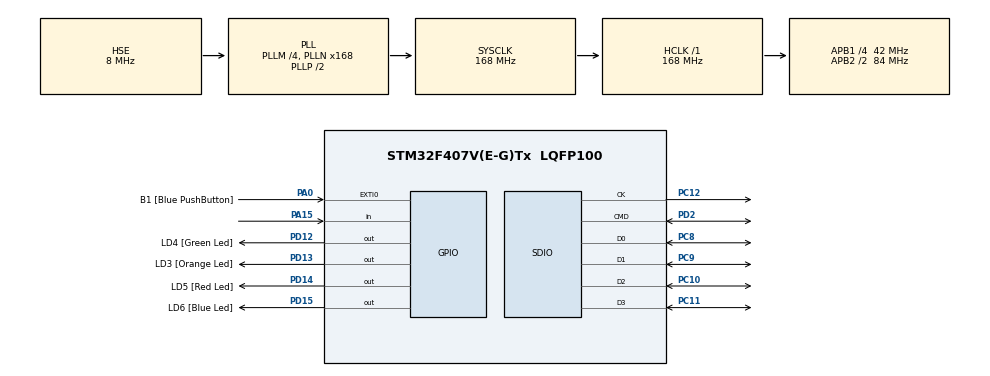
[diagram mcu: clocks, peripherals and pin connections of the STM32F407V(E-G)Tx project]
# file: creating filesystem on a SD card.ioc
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Dma.Request0=SDIO_RX
Dma.Request1=SDIO_TX
Dma.SDIO_RX.0.Direction=DMA_PERIPH_TO_MEMORY
Dma.SDIO_RX.0.FIFOMode=DMA_FIFOMODE_ENABLE
Dma.SDIO_RX.0.FIFOThreshold=DMA_FIFO_THRESHOLD_FULL
Dma.SDIO_RX.0.Instance=DMA2_Stream3
Dma.SDIO_RX.0.MemBurst=DMA_MBURST_INC4
Dma.SDIO_RX.0.MemDataAlignment=DMA_MDATAALIGN_WORD
Dma.SDIO_RX.0.MemInc=DMA_MINC_ENABLE
Dma.SDIO_RX.0.Mode=DMA_PFCTRL
Dma.SDIO_RX.0.PeriphBurst=DMA_PBURST_INC4
Dma.SDIO_RX.0.PeriphDataAlignment=DMA_PDATAALIGN_WORD
Dma.SDIO_RX.0.PeriphInc=DMA_PINC_DISABLE
Dma.SDIO_RX.0.Priority=DMA_PRIORITY_LOW
Dma.SDIO_TX.1.Direction=DMA_MEMORY_TO_PERIPH
Dma.SDIO_TX.1.FIFOMode=DMA_FIFOMODE_ENABLE
Dma.SDIO_TX.1.FIFOThreshold=DMA_FIFO_THRESHOLD_FULL
Dma.SDIO_TX.1.Instance=DMA2_Stream6
Dma.SDIO_TX.1.MemBurst=DMA_MBURST_INC4
Dma.SDIO_TX.1.MemDataAlignment=DMA_MDATAALIGN_WORD
Dma.SDIO_TX.1.MemInc=DMA_MINC_ENABLE
Dma.SDIO_TX.1.Mode=DMA_PFCTRL
Dma.SDIO_TX.1.PeriphBurst=DMA_PBURST_INC4
Dma.SDIO_TX.1.PeriphDataAlignment=DMA_PDATAALIGN_WORD
Dma.SDIO_TX.1.PeriphInc=DMA_PINC_DISABLE
Dma.SDIO_TX.1.Priority=DMA_PRIORITY_LOW
FATFS.BSP.number=1
FATFS.USE_DMA_CODE_SD=1
FATFS._MAX_SS=4096
FATFS._USE_LFN=1
FATFS0.BSP.STBoard=false
FATFS0.BSP.api=Unknown
FATFS0.BSP.i2caddr=0
FATFS0.BSP.instance=PA15
FATFS0.BSP.ip=GPIO
FATFS0.BSP.mode=Input
FATFS0.BSP.name=Detect_SDIO
FATFS0.BSP.solution=PA15
Mcu.Family=STM32F4
Mcu.Name=STM32F407V(E-G)Tx
Mcu.Package=LQFP100
NVIC.DMA2_Stream3_IRQn=true\:0\:0\:false\:false\:true\:false\:true
NVIC.DMA2_Stream6_IRQn=true\:0\:0\:false\:false\:true\:false\:true
NVIC.PriorityGroup=NVIC_PRIORITYGROUP_0
NVIC.SDIO_IRQn=true\:0\:0\:false\:false\:true\:true\:true
PA0-WKUP.GPIO_Label=B1 [Blue PushButton]
PA0-WKUP.Signal=GPXTI0
PA13.GPIO_Label=SWDIO
PA13.Mode=Serial_Wire
PA13.Signal=SYS_JTMS-SWDIO
PA14.GPIO_Label=SWCLK
PA14.Mode=Serial_Wire
PA14.Signal=SYS_JTCK-SWCLK
PA15.Signal=GPIO_Input
PC10.Mode=SD_4_bits_Wide_bus
PC10.Signal=SDIO_D2
PC11.Mode=SD_4_bits_Wide_bus
PC11.Signal=SDIO_D3
PC12.Mode=SD_4_bits_Wide_bus
PC12.Signal=SDIO_CK
PC8.Mode=SD_4_bits_Wide_bus
PC8.Signal=SDIO_D0
PC9.Mode=SD_4_bits_Wide_bus
PC9.Signal=SDIO_D1
PD12.GPIO_Label=LD4 [Green Led]
PD12.GPIO_PuPd=GPIO_NOPULL
PD12.GPIO_Speed=GPIO_SPEED_FREQ_LOW
PD12.Signal=GPIO_Output
PD13.GPIO_Label=LD3 [Orange Led]
PD13.GPIO_PuPd=GPIO_NOPULL
PD13.GPIO_Speed=GPIO_SPEED_FREQ_LOW
PD13.Signal=GPIO_Output
PD14.GPIO_Label=LD5 [Red Led]
PD14.GPIO_PuPd=GPIO_NOPULL
PD14.GPIO_Speed=GPIO_SPEED_FREQ_LOW
PD14.Signal=GPIO_Output
PD15.GPIO_Label=LD6 [Blue Led]
PD15.GPIO_PuPd=GPIO_NOPULL
PD15.GPIO_Speed=GPIO_SPEED_FREQ_LOW
PD15.Signal=GPIO_Output
PD2.Mode=SD_4_bits_Wide_bus
PD2.Signal=SDIO_CMD
PH0-OSC_IN.Mode=HSE-External-Oscillator
PH0-OSC_IN.Signal=RCC_OSC_IN
PH1-OSC_OUT.Mode=HSE-External-Oscillator
PH1-OSC_OUT.Signal=RCC_OSC_OUT
ProjectManager.HeapSize=0x400
ProjectManager.StackSize=0x800
ProjectManager.TargetToolchain=STM32CubeIDE
RCC.48MHZClocksFreq_Value=48000000
RCC.AHBFreq_Value=168000000
RCC.APB1CLKDivider=RCC_HCLK_DIV4
RCC.APB1Freq_Value=42000000
RCC.APB1TimFreq_Value=84000000
RCC.APB2CLKDivider=RCC_HCLK_DIV2
RCC.APB2Freq_Value=84000000
RCC.APB2TimFreq_Value=168000000
RCC.CortexFreq_Value=168000000
RCC.HCLKFreq_Value=168000000
RCC.HSE_VALUE=8000000
RCC.HSI_VALUE=16000000
RCC.LSE_VALUE=32768
RCC.PLLM=4
RCC.PLLN=168
RCC.PLLQ=7
RCC.PLLSourceVirtual=RCC_PLLSOURCE_HSE
RCC.SYSCLKFreq_VALUE=168000000
RCC.SYSCLKSource=RCC_SYSCLKSOURCE_PLLCLK
RCC.VCOOutputFreq_Value=336000000
SDIO.ClockDiv=5
VP_FATFS_VS_SDIO.Mode=SDIO
board=STM32F407G-DISC1

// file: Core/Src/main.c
/* USER CODE BEGIN Header */
/**
  ******************************************************************************
  * @file           : main.c
  * @brief          : Main program body
  ******************************************************************************
  * @attention
  *
  * <h2><center>&copy; Copyright (c) 2021 STMicroelectronics.
  * All rights reserved.</center></h2>
  *
  * This software component is licensed by ST under Ultimate Liberty license
  * SLA0044, the "License"; You may not use this file except in compliance with
  * the License. You may obtain a copy of the License at:
  *                             www.st.com/SLA0044
  *
  ******************************************************************************
  */
/* USER CODE END Header */
#include "main.h"
#include "fatfs.h"

SD_HandleTypeDef hsd;
DMA_HandleTypeDef hdma_sdio_rx;
DMA_HandleTypeDef hdma_sdio_tx;

void SystemClock_Config(void);
static void MX_GPIO_Init(void);
static void MX_DMA_Init(void);
static void MX_SDIO_SD_Init(void);

int main(void)
{
  /* USER CODE BEGIN 1 */
FRESULT res;
uint32_t byteswritten, bytesread;
uint8_t wtext[] = "stm32 fatfs works great!";
uint8_t rtext[_MAX_SS];
  /* USER CODE END 1 */

  /* MCU Configuration--------------------------------------------------------*/

  /* Reset of all peripherals, Initializes the Flash interface and the Systick. */
  HAL_Init();

  /* Configure the system clock */
  SystemClock_Config();

  /* Initialize all configured peripherals */
  MX_GPIO_Init();
  MX_DMA_Init();
  MX_SDIO_SD_Init();
  MX_FATFS_Init();
  /* USER CODE BEGIN 2 */
res=f_mount(&SDFatFS, (TCHAR const*)SDPath, 0);
res=f_mkfs((TCHAR const *)SDPath, FM_ANY, 0, rtext, sizeof(rtext));
res=f_open(&SDFile, "STM32.txt",FA_CREATE_ALWAYS | FA_WRITE);
res = f_write(&SDFile, wtext, strlen((char *)wtext), (void *)&byteswritten);
res=f_close(&SDFile);
res=f_mount(&SDFatFS, (TCHAR const*)NULL, 0);
  /* USER CODE END 2 */

  /* Infinite loop */
  while (1)
  {

  }
}

void SystemClock_Config(void)
{
  RCC_OscInitTypeDef RCC_OscInitStruct = {0};
  RCC_ClkInitTypeDef RCC_ClkInitStruct = {0};

  /** Configure the main internal regulator output voltage
  */
  __HAL_RCC_PWR_CLK_ENABLE();
  __HAL_PWR_VOLTAGESCALING_CONFIG(PWR_REGULATOR_VOLTAGE_SCALE1);
  /** Initializes the RCC Oscillators according to the specified parameters
  * in the RCC_OscInitTypeDef structure.
  */
  RCC_OscInitStruct.OscillatorType = RCC_OSCILLATORTYPE_HSE;
  RCC_OscInitStruct.HSEState = RCC_HSE_ON;
  RCC_OscInitStruct.PLL.PLLState = RCC_PLL_ON;
  RCC_OscInitStruct.PLL.PLLSource = RCC_PLLSOURCE_HSE;
  RCC_OscInitStruct.PLL.PLLM = 4;
  RCC_OscInitStruct.PLL.PLLN = 168;
  RCC_OscInitStruct.PLL.PLLP = RCC_PLLP_DIV2;
  RCC_OscInitStruct.PLL.PLLQ = 7;
  if (HAL_RCC_OscConfig(&RCC_OscInitStruct) != HAL_OK)
  {
    Error_Handler();
  }
  /** Initializes the CPU, AHB and APB buses clocks
  */
  RCC_ClkInitStruct.ClockType = RCC_CLOCKTYPE_HCLK|RCC_CLOCKTYPE_SYSCLK
                              |RCC_CLOCKTYPE_PCLK1|RCC_CLOCKTYPE_PCLK2;
  RCC_ClkInitStruct.SYSCLKSource = RCC_SYSCLKSOURCE_PLLCLK;
  RCC_ClkInitStruct.AHBCLKDivider = RCC_SYSCLK_DIV1;
  RCC_ClkInitStruct.APB1CLKDivider = RCC_HCLK_DIV4;
  RCC_ClkInitStruct.APB2CLKDivider = RCC_HCLK_DIV2;

  if (HAL_RCC_ClockConfig(&RCC_ClkInitStruct, FLASH_LATENCY_5) != HAL_OK)
  {
    Error_Handler();
  }
}

static void MX_SDIO_SD_Init(void)
{

  hsd.Instance = SDIO;
  hsd.Init.ClockEdge = SDIO_CLOCK_EDGE_RISING;
  hsd.Init.ClockBypass = SDIO_CLOCK_BYPASS_DISABLE;
  hsd.Init.ClockPowerSave = SDIO_CLOCK_POWER_SAVE_DISABLE;
  hsd.Init.BusWide = SDIO_BUS_WIDE_1B;
  hsd.Init.HardwareFlowControl = SDIO_HARDWARE_FLOW_CONTROL_DISABLE;
  hsd.Init.ClockDiv = 5;

}

static void MX_DMA_Init(void)
{

  /* DMA controller clock enable */
  __HAL_RCC_DMA2_CLK_ENABLE();

  /* DMA interrupt init */
  /* DMA2_Stream3_IRQn interrupt configuration */
  HAL_NVIC_SetPriority(DMA2_Stream3_IRQn, 0, 0);
  HAL_NVIC_EnableIRQ(DMA2_Stream3_IRQn);
  /* DMA2_Stream6_IRQn interrupt configuration */
  HAL_NVIC_SetPriority(DMA2_Stream6_IRQn, 0, 0);
  HAL_NVIC_EnableIRQ(DMA2_Stream6_IRQn);

}

static void MX_GPIO_Init(void)
{
  GPIO_InitTypeDef GPIO_InitStruct = {0};

  /* GPIO Ports Clock Enable */
  __HAL_RCC_GPIOH_CLK_ENABLE();
  __HAL_RCC_GPIOA_CLK_ENABLE();
  __HAL_RCC_GPIOD_CLK_ENABLE();
  __HAL_RCC_GPIOC_CLK_ENABLE();

  /*Configure GPIO pin Output Level */
  HAL_GPIO_WritePin(GPIOD, LD4_Pin|LD3_Pin|LD5_Pin|LD6_Pin, GPIO_PIN_RESET);

  /*Configure GPIO pin : B1_Pin */
  GPIO_InitStruct.Pin = B1_Pin;
  GPIO_InitStruct.Mode = GPIO_MODE_IT_RISING;
  GPIO_InitStruct.Pull = GPIO_NOPULL;
  HAL_GPIO_Init(B1_GPIO_Port, &GPIO_InitStruct);

  /*Configure GPIO pins : LD4_Pin LD3_Pin LD5_Pin LD6_Pin */
  GPIO_InitStruct.Pin = LD4_Pin|LD3_Pin|LD5_Pin|LD6_Pin;
  GPIO_InitStruct.Mode = GPIO_MODE_OUTPUT_PP;
  GPIO_InitStruct.Pull = GPIO_NOPULL;
  GPIO_InitStruct.Speed = GPIO_SPEED_FREQ_LOW;
  HAL_GPIO_Init(GPIOD, &GPIO_InitStruct);

  /*Configure GPIO pin : PA15 */
  GPIO_InitStruct.Pin = GPIO_PIN_15;
  GPIO_InitStruct.Mode = GPIO_MODE_INPUT;
  GPIO_InitStruct.Pull = GPIO_NOPULL;
  HAL_GPIO_Init(GPIOA, &GPIO_InitStruct);

}

void Error_Handler(void)
{
}

/************************ (C) COPYRIGHT STMicroelectronics *****END OF FILE****/
